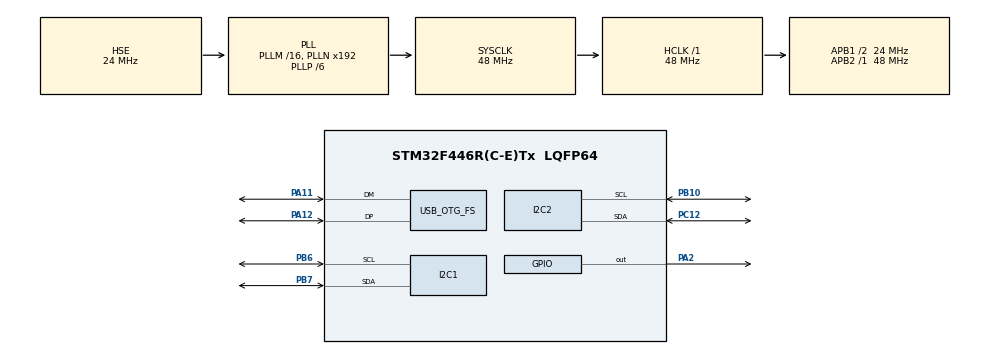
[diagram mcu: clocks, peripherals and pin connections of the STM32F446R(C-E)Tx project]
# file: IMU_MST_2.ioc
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I2C1.I2C_Mode=I2C_Fast
I2C2.I2C_Mode=I2C_Fast
Mcu.Family=STM32F4
Mcu.Name=STM32F446R(C-E)Tx
Mcu.Package=LQFP64
NVIC.OTG_FS_IRQn=true\:0\:0\:false\:true\:true\:2\:false\:true\:true
NVIC.PriorityGroup=NVIC_PRIORITYGROUP_4
NVIC.TIM1_UP_TIM10_IRQn=true\:0\:0\:false\:true\:true\:1\:true\:true\:true
PA11.Mode=Device_Only
PA11.Signal=USB_OTG_FS_DM
PA12.Mode=Device_Only
PA12.Signal=USB_OTG_FS_DP
PA13.Mode=Serial_Wire
PA13.Signal=SYS_JTMS-SWDIO
PA14.Mode=Serial_Wire
PA14.Signal=SYS_JTCK-SWCLK
PA2.GPIO_ModeDefaultOutputPP=GPIO_MODE_OUTPUT_PP
PA2.GPIO_PuPd=GPIO_NOPULL
PA2.GPIO_Speed=GPIO_SPEED_FREQ_HIGH
PA2.Signal=GPIO_Output
PB10.Mode=I2C
PB10.Signal=I2C2_SCL
PB6.Mode=I2C
PB6.Signal=I2C1_SCL
PB7.Mode=I2C
PB7.Signal=I2C1_SDA
PC12.Mode=I2C
PC12.Signal=I2C2_SDA
PH0-OSC_IN.Mode=HSE-External-Oscillator
PH0-OSC_IN.Signal=RCC_OSC_IN
PH1-OSC_OUT.Mode=HSE-External-Oscillator
PH1-OSC_OUT.Signal=RCC_OSC_OUT
ProjectManager.HeapSize=0x200
ProjectManager.StackSize=0x400
ProjectManager.TargetToolchain=STM32CubeIDE
RCC.AHBFreq_Value=48000000
RCC.APB1CLKDivider=RCC_HCLK_DIV2
RCC.APB1Freq_Value=24000000
RCC.APB1TimFreq_Value=48000000
RCC.APB2Freq_Value=48000000
RCC.APB2TimFreq_Value=48000000
RCC.CortexFreq_Value=48000000
RCC.HCLKFreq_Value=48000000
RCC.HSE_VALUE=24000000
RCC.PLLP=RCC_PLLP_DIV6
RCC.PLLQ=6
RCC.SYSCLKFreq_VALUE=48000000
RCC.SYSCLKSource=RCC_SYSCLKSOURCE_PLLCLK
RCC.USBFreq_Value=48000000
RCC.VCOOutputFreq_Value=288000000
TIM1.Period=168
TIM1.Prescaler=2730
USB_DEVICE.CLASS_NAME_FS=CDC
USB_DEVICE.VirtualMode-CDC_FS=Cdc
USB_DEVICE.VirtualModeFS=Cdc_FS
USB_OTG_FS.VirtualMode=Device_Only
VP_TIM1_VS_ClockSourceINT.Mode=Internal
VP_USB_DEVICE_VS_USB_DEVICE_CDC_FS.Mode=CDC_FS
board=custom

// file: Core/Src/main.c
/* USER CODE BEGIN Header */
/**
  ******************************************************************************
  * @file           : main.c
  * @brief          : Main program body
  ******************************************************************************
  * @attention
  *
  * Copyright (c) 2026 STMicroelectronics.
  * All rights reserved.
  *
  * This software is licensed under terms that can be found in the LICENSE file
  * in the root directory of this software component.
  * If no LICENSE file comes with this software, it is provided AS-IS.
  *
  ******************************************************************************
  */
/* USER CODE END Header */
#include "main.h"
#include "usb_device.h"

/* USER CODE BEGIN Includes */
#include "imu_transport.h"
#include "usbd_cdc_if.h"
#include "usbd_cdc.h"
/* USER CODE END Includes */

I2C_HandleTypeDef hi2c1;
I2C_HandleTypeDef hi2c2;

TIM_HandleTypeDef htim1;

void SystemClock_Config(void);
static void MX_GPIO_Init(void);
static void MX_I2C1_Init(void);
static void MX_I2C2_Init(void);
static void MX_TIM1_Init(void);
static void MX_NVIC_Init(void);

int main(void)
{

  /* MCU Configuration--------------------------------------------------------*/

  /* Reset of all peripherals, Initializes the Flash interface and the Systick. */
  HAL_Init();

  /* Configure the system clock */
  SystemClock_Config();

  /* Initialize all configured peripherals */
  MX_GPIO_Init();
  MX_I2C1_Init();
  MX_I2C2_Init();
  MX_USB_DEVICE_Init();
  MX_TIM1_Init();

  /* Initialize interrupts */
  MX_NVIC_Init();
  /* USER CODE BEGIN 2 */
  HAL_GPIO_WritePin(GPIOA, GPIO_PIN_2, GPIO_PIN_SET);

  if (HAL_TIM_Base_Start_IT(&htim1) != HAL_OK) Error_Handler();

  /* USER CODE END 2 */

  /* Infinite loop */
  /* USER CODE BEGIN WHILE */
  while (1)
  {
    imu_transport_poll();
    /* USER CODE END WHILE */

  }
}

void SystemClock_Config(void)
{
  RCC_OscInitTypeDef RCC_OscInitStruct = {0};
  RCC_ClkInitTypeDef RCC_ClkInitStruct = {0};

  /** Configure the main internal regulator output voltage
  */
  __HAL_RCC_PWR_CLK_ENABLE();
  __HAL_PWR_VOLTAGESCALING_CONFIG(PWR_REGULATOR_VOLTAGE_SCALE3);

  /** Initializes the RCC Oscillators according to the specified parameters
  * in the RCC_OscInitTypeDef structure.
  */
  RCC_OscInitStruct.OscillatorType = RCC_OSCILLATORTYPE_HSE;
  RCC_OscInitStruct.HSEState = RCC_HSE_ON;
  RCC_OscInitStruct.PLL.PLLState = RCC_PLL_ON;
  RCC_OscInitStruct.PLL.PLLSource = RCC_PLLSOURCE_HSE;
  RCC_OscInitStruct.PLL.PLLM = 16;
  RCC_OscInitStruct.PLL.PLLN = 192;
  RCC_OscInitStruct.PLL.PLLP = RCC_PLLP_DIV6;
  RCC_OscInitStruct.PLL.PLLQ = 6;
  RCC_OscInitStruct.PLL.PLLR = 2;
  if (HAL_RCC_OscConfig(&RCC_OscInitStruct) != HAL_OK)
  {
    Error_Handler();
  }

  /** Initializes the CPU, AHB and APB buses clocks
  */
  RCC_ClkInitStruct.ClockType = RCC_CLOCKTYPE_HCLK|RCC_CLOCKTYPE_SYSCLK
                              |RCC_CLOCKTYPE_PCLK1|RCC_CLOCKTYPE_PCLK2;
  RCC_ClkInitStruct.SYSCLKSource = RCC_SYSCLKSOURCE_PLLCLK;
  RCC_ClkInitStruct.AHBCLKDivider = RCC_SYSCLK_DIV1;
  RCC_ClkInitStruct.APB1CLKDivider = RCC_HCLK_DIV2;
  RCC_ClkInitStruct.APB2CLKDivider = RCC_HCLK_DIV1;

  if (HAL_RCC_ClockConfig(&RCC_ClkInitStruct, FLASH_LATENCY_1) != HAL_OK)
  {
    Error_Handler();
  }
}

/**
  * @brief NVIC Configuration.
  * @retval None
  */
static void MX_NVIC_Init(void)
{
  /* TIM1_UP_TIM10_IRQn interrupt configuration */
  HAL_NVIC_SetPriority(TIM1_UP_TIM10_IRQn, 0, 0);
  HAL_NVIC_EnableIRQ(TIM1_UP_TIM10_IRQn);
  /* OTG_FS_IRQn interrupt configuration */
  HAL_NVIC_SetPriority(OTG_FS_IRQn, 0, 0);
  HAL_NVIC_EnableIRQ(OTG_FS_IRQn);
}

static void MX_I2C1_Init(void)
{

  hi2c1.Instance = I2C1;
  hi2c1.Init.ClockSpeed = 400000;
  hi2c1.Init.DutyCycle = I2C_DUTYCYCLE_2;
  hi2c1.Init.OwnAddress1 = 0;
  hi2c1.Init.AddressingMode = I2C_ADDRESSINGMODE_7BIT;
  hi2c1.Init.DualAddressMode = I2C_DUALADDRESS_DISABLE;
  hi2c1.Init.OwnAddress2 = 0;
  hi2c1.Init.GeneralCallMode = I2C_GENERALCALL_DISABLE;
  hi2c1.Init.NoStretchMode = I2C_NOSTRETCH_DISABLE;
  if (HAL_I2C_Init(&hi2c1) != HAL_OK)
  {
    Error_Handler();
  }

}

static void MX_I2C2_Init(void)
{

  hi2c2.Instance = I2C2;
  hi2c2.Init.ClockSpeed = 400000;
  hi2c2.Init.DutyCycle = I2C_DUTYCYCLE_2;
  hi2c2.Init.OwnAddress1 = 0;
  hi2c2.Init.AddressingMode = I2C_ADDRESSINGMODE_7BIT;
  hi2c2.Init.DualAddressMode = I2C_DUALADDRESS_DISABLE;
  hi2c2.Init.OwnAddress2 = 0;
  hi2c2.Init.GeneralCallMode = I2C_GENERALCALL_DISABLE;
  hi2c2.Init.NoStretchMode = I2C_NOSTRETCH_DISABLE;
  if (HAL_I2C_Init(&hi2c2) != HAL_OK)
  {
    Error_Handler();
  }

}

static void MX_TIM1_Init(void)
{

  TIM_ClockConfigTypeDef sClockSourceConfig = {0};
  TIM_MasterConfigTypeDef sMasterConfig = {0};

  htim1.Instance = TIM1;
  htim1.Init.Prescaler = 2730;
  htim1.Init.CounterMode = TIM_COUNTERMODE_UP;
  htim1.Init.Period = 168;
  htim1.Init.ClockDivision = TIM_CLOCKDIVISION_DIV1;
  htim1.Init.RepetitionCounter = 0;
  htim1.Init.AutoReloadPreload = TIM_AUTORELOAD_PRELOAD_DISABLE;
  if (HAL_TIM_Base_Init(&htim1) != HAL_OK)
  {
    Error_Handler();
  }
  sClockSourceConfig.ClockSource = TIM_CLOCKSOURCE_INTERNAL;
  if (HAL_TIM_ConfigClockSource(&htim1, &sClockSourceConfig) != HAL_OK)
  {
    Error_Handler();
  }
  sMasterConfig.MasterOutputTrigger = TIM_TRGO_RESET;
  sMasterConfig.MasterSlaveMode = TIM_MASTERSLAVEMODE_DISABLE;
  if (HAL_TIMEx_MasterConfigSynchronization(&htim1, &sMasterConfig) != HAL_OK)
  {
    Error_Handler();
  }

}

static void MX_GPIO_Init(void)
{
  GPIO_InitTypeDef GPIO_InitStruct = {0};

  /* GPIO Ports Clock Enable */
  __HAL_RCC_GPIOH_CLK_ENABLE();
  __HAL_RCC_GPIOA_CLK_ENABLE();
  __HAL_RCC_GPIOB_CLK_ENABLE();
  __HAL_RCC_GPIOC_CLK_ENABLE();

  /*Configure GPIO pin Output Level */
  HAL_GPIO_WritePin(GPIOA, GPIO_PIN_2, GPIO_PIN_RESET);

  /*Configure GPIO pin : PA2 */
  GPIO_InitStruct.Pin = GPIO_PIN_2;
  GPIO_InitStruct.Mode = GPIO_MODE_OUTPUT_PP;
  GPIO_InitStruct.Pull = GPIO_NOPULL;
  GPIO_InitStruct.Speed = GPIO_SPEED_FREQ_HIGH;
  HAL_GPIO_Init(GPIOA, &GPIO_InitStruct);

}

/* USER CODE BEGIN 4 */
void HAL_TIM_PeriodElapsedCallback(TIM_HandleTypeDef* htim)
{
	if (htim->Instance == TIM1) imu_transport_timer();
}
/* USER CODE END 4 */

void Error_Handler(void)
{
  __disable_irq();
  while (1)
  {
  }
}
